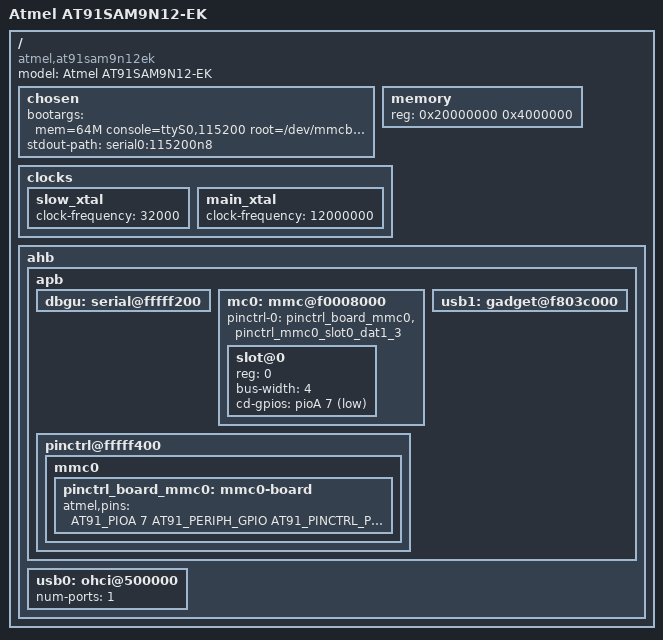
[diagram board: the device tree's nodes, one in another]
/*
 * at91sam9n12ek.dts - Device Tree file for AT91SAM9N12-EK board
 *
 *  Copyright (C) 2012 Atmel,
 *                2012 Hong Xu <hong.xu@atmel.com>
 *
 * Licensed under GPLv2 or later.
 */
/dts-v1/;
#include "at91sam9n12.dtsi"

/ {
    model = "Atmel AT91SAM9N12-EK";
    compatible = "atmel,at91sam9n12ek", "atmel,at91sam9n12", "atmel,at91sam9";

    chosen {
        bootargs = "mem=64M console=ttyS0,115200 root=/dev/mmcblk0p2 rw rootfstype=ext4 rootwait";
        stdout-path = "serial0:115200n8";
    };

    memory {
        /* 64 MB */
        reg = <0x20000000 0x4000000>;
    };

    clocks {
        slow_xtal {
            clock-frequency = <32000>;
        };

        main_xtal {
            clock-frequency = <12000000>;
        };
    };

    ahb {
        apb {
            dbgu: serial@fffff200 {
                status = "okay";
            };

            mc0: mmc@f0008000 {
                pinctrl-0 = <
                    &pinctrl_board_mmc0
                    &pinctrl_mmc0_slot0_dat1_3>;
                status = "okay";
                slot@0 {
                    reg = <0>;
                    bus-width = <4>;
                    cd-gpios = <&pioA 7 GPIO_ACTIVE_LOW>;
                };
            };
            
            pinctrl@fffff400 {
                mmc0 {
                    pinctrl_board_mmc0: mmc0-board {
                        atmel,pins = <AT91_PIOA 7 AT91_PERIPH_GPIO AT91_PINCTRL_PULL_UP_DEGLITCH>;    /* SD Card gpio CD pin pull up and deglitch */         
                    };
                };
            };
            
            usb1: gadget@f803c000 {
                status = "okay";
            }; 
        };

        usb0: ohci@500000 {
            num-ports = <1>;
            status = "okay";
        };
    };
};
